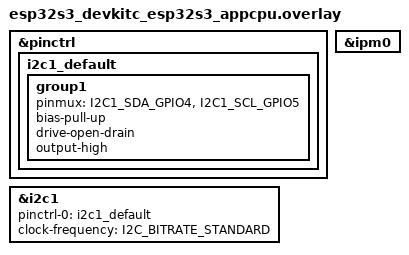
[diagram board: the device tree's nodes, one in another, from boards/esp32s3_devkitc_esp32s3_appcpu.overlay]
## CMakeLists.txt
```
cmake_minimum_required(VERSION 3.20.0)

find_package(Zephyr REQUIRED HINTS $ENV{ZEPHYR_BASE})
project(hw664_lis3dh_appcpu)

target_sources(app PRIVATE
	src/main.c
	src/ssd1306_display.c
)
```

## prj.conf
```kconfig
# 03_HW664_LIS3DH - core1 (appcpu) image
#
# This core never touches the accelerometer, only the SSD1306 over I2C1 and
# the IPM mailbox from core0.

CONFIG_I2C=y
CONFIG_GPIO=y

CONFIG_IPM=y
CONFIG_ESP32_SOFT_IPM=y

CONFIG_LOG=y
CONFIG_LOG_MODE_IMMEDIATE=y

CONFIG_FPU=y
```

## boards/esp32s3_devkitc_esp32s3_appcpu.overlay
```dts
/*
 * Overlay for 03_HW664_LIS3DH - core1 (appcpu) image
 *
 * Identical convention to Lab 01: I2C1 (NOT I2C0) at SDA=GPIO4 /
 * SCL=GPIO5, since core1 must own a physically different I2C
 * controller than core0's LIS3DSH bus. No sensor devicetree nodes
 * here - core1 never talks to the LIS3DSH directly, only to the
 * SSD1306 (probed at runtime by src/ssd1306_display.c).
 */

#include <dt-bindings/pinctrl/esp32s3-pinctrl.h>
#include <zephyr/dt-bindings/i2c/i2c.h>

&pinctrl {
	i2c1_default: i2c1_default {
		group1 {
			pinmux = <I2C1_SDA_GPIO4>, <I2C1_SCL_GPIO5>;
			bias-pull-up;
			drive-open-drain;
			output-high;
		};
	};
};

&i2c1 {
	status = "okay";
	pinctrl-0 = <&i2c1_default>;
	pinctrl-names = "default";
	clock-frequency = <I2C_BITRATE_STANDARD>; /* 100 kHz */
};

&ipm0 {
	status = "okay";
};
```

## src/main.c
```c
/*
 * main.c - 03_HW664_LIS3DH (core1 / appcpu image)
 *
 * CHIP IDENTITY CORRECTION (2026-09-04): the actual chip on this board
 * is an ST LIS3DH (WHO_AM_I=0x33 confirmed on real hardware), not a
 * genuine LIS3DSH (which would read 0x3F) despite the module's
 * silkscreen/listing. This core doesn't care either way - it only
 * ever sees the 3 accel values core0 forwards over IPM.
 *
 * Same pattern as Lab 01/02's core1: receive sensor snapshots from
 * core0 over IPM and draw them on the SSD1306. This core never touches
 * I2C0 or the accelerometer directly.
 *
 * Event flow: the ESP32 IPM driver invokes `ipm_callback()` in
 * interrupt context whenever core0 sends a message. ISR context must
 * stay short, so the callback only copies the payload into a message
 * queue (k_msgq_put with K_NO_WAIT is ISR-safe) and returns
 * immediately. The actual OLED redraw happens in `display_thread_fn()`,
 * which blocks on `k_msgq_get()` and only wakes when a new sample has
 * actually arrived.
 *
 * core0 pushes immediately when the accel vector magnitude moves past
 * a threshold since the last value it sent, plus a 1s heartbeat so
 * this side has something to declare "alive" during quiet periods.
 * This side only cares about elapsed time since the last arrival: if
 * nothing shows up in `sensor_msgq` for 2 s, the link is considered
 * down.
 */

#include <zephyr/kernel.h>
#include <zephyr/device.h>
#include <zephyr/drivers/i2c.h>
#include <zephyr/drivers/ipm.h>
#include <zephyr/logging/log.h>
#include <string.h>

#include "ipm_protocol.h"
#include "ssd1306_display.h"

LOG_MODULE_REGISTER(app_appcpu, LOG_LEVEL_INF);

static const struct device *dev_i2c1 = DEVICE_DT_GET(DT_NODELABEL(i2c1));
static const struct device *dev_ipm  = DEVICE_DT_GET(DT_NODELABEL(ipm0));

K_MSGQ_DEFINE(sensor_msgq, sizeof(struct ipm_sensor_payload), 4, 4);

/* Runs in IPM ISR context - keep it minimal. */
static void ipm_callback(const struct device *ipmdev, void *user_data,
			  uint32_t id, volatile void *data)
{
	ARG_UNUSED(ipmdev);
	ARG_UNUSED(user_data);

	if (id != IPM_SENSOR_CHANNEL) {
		return; /* not our channel - ignore */
	}

	struct ipm_sensor_payload payload;

	memcpy(&payload, (const void *)data, sizeof(payload));

	if (k_msgq_put(&sensor_msgq, &payload, K_NO_WAIT) != 0) {
		struct ipm_sensor_payload discard;

		k_msgq_get(&sensor_msgq, &discard, K_NO_WAIT);
		k_msgq_put(&sensor_msgq, &payload, K_NO_WAIT);
	}
}

static void format_fixed(float value, int decimals, char *buf, size_t buf_len)
{
	bool negative = value < 0.0f;
	float abs_value = negative ? -value : value;
	int scale = (decimals == 2) ? 100 : 10;
	int scaled = (int)(abs_value * scale + 0.5f);

	if (decimals == 2) {
		snprintf(buf, buf_len, "%s%d.%02d", negative ? "-" : "",
			  scaled / scale, scaled % scale);
	} else {
		snprintf(buf, buf_len, "%s%d.%d", negative ? "-" : "",
			  scaled / scale, scaled % scale);
	}
}

static void render_payload(const struct ipm_sensor_payload *p, bool stale)
{
	char line[22];
	char num[10];

	ssd1306_clear();

	/* Link health goes first/top - it qualifies how much to trust
	 * everything else on the screen.
	 */
	ssd1306_draw_text(0, 0, stale ? "LINK: FAIL" : "LINK: OK");

	if (p->valid) {
		format_fixed(p->accel_x_g, 2, num, sizeof(num));
		snprintf(line, sizeof(line), "AX:%s", num);
		ssd1306_draw_text(2, 0, line);

		format_fixed(p->accel_y_g, 2, num, sizeof(num));
		snprintf(line, sizeof(line), "AY:%s", num);
		ssd1306_draw_text(3, 0, line);

		format_fixed(p->accel_z_g, 2, num, sizeof(num));
		snprintf(line, sizeof(line), "AZ:%s", num);
		ssd1306_draw_text(4, 0, line);
	} else {
		ssd1306_draw_text(3, 0, "LIS3DH ---");
	}

	ssd1306_flush();
}

static void display_thread_fn(void *p1, void *p2, void *p3)
{
	ARG_UNUSED(p1);
	ARG_UNUSED(p2);
	ARG_UNUSED(p3);

	int ret = ssd1306_display_init(dev_i2c1);

	if (ret) {
		LOG_ERR("SSD1306 init failed: %d - display thread exiting", ret);
		return;
	}

	ssd1306_draw_text(3, 0, "WAITING FOR");
	ssd1306_draw_text(4, 0, "CORE0...");
	ssd1306_flush();

	bool have_data = false;
	struct ipm_sensor_payload last_payload = { 0 };

	while (1) {
		struct ipm_sensor_payload payload;
		int ret2 = k_msgq_get(&sensor_msgq, &payload, K_MSEC(2000));

		if (ret2 == 0) {
			last_payload = payload;
			have_data = true;
			render_payload(&last_payload, false);
		} else if (have_data) {
			render_payload(&last_payload, true);
		}
	}
}

K_THREAD_DEFINE(display_tid, 2048, display_thread_fn, NULL, NULL, NULL, 6, 0, 0);

int main(void)
{
	LOG_INF("03_HW664_LIS3DH (core1/appcpu) starting");

	if (!device_is_ready(dev_i2c1)) {
		LOG_ERR("I2C1 bus not ready");
		return -1;
	}
	if (!device_is_ready(dev_ipm)) {
		LOG_ERR("IPM device not ready - cannot receive sensor data from core0");
		return -1;
	}

	ipm_register_callback(dev_ipm, ipm_callback, NULL);
	ipm_set_enabled(dev_ipm, 1);

	/* display_thread_fn is already running (K_THREAD_DEFINE, 0 delay). */
	return 0;
}
```

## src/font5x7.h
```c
/*
 * font5x7.h
 *
 * Minimal original 5x7 dot-matrix font for the SSD1306 text
 * renderer used across this multi-sensor lab series. Only the
 * characters this series actually prints (labels, digits,
 * units, punctuation) are defined; anything else falls back
 * to a blank glyph in font5x7_lookup().
 *
 * Layout: 5 columns per glyph, column-major, bit0 = top row,
 * 7 rows tall (fits an 8px-tall character cell with 1px gap).
 */

#ifndef FONT5X7_H_
#define FONT5X7_H_

#include <stdint.h>
#include <stddef.h>
#include <zephyr/sys/util.h> /* ARRAY_SIZE */

#define FONT5X7_WIDTH  5
#define FONT5X7_HEIGHT 7

static const uint8_t FONT_SPACE[FONT5X7_WIDTH] = {0x00, 0x00, 0x00, 0x00, 0x00};
static const uint8_t FONT_BANG[FONT5X7_WIDTH] = {0x00, 0x5F, 0x5F, 0x00, 0x00};
static const uint8_t FONT_PERCENT[FONT5X7_WIDTH] = {0x21, 0x10, 0x0C, 0x02, 0x21};
static const uint8_t FONT_DASH[FONT5X7_WIDTH] = {0x08, 0x08, 0x08, 0x08, 0x08};
static const uint8_t FONT_DOT[FONT5X7_WIDTH] = {0x00, 0x60, 0x60, 0x00, 0x00};
static const uint8_t FONT_0[FONT5X7_WIDTH] = {0x3E, 0x51, 0x49, 0x45, 0x3E};
static const uint8_t FONT_1[FONT5X7_WIDTH] = {0x00, 0x42, 0x7F, 0x40, 0x00};
static const uint8_t FONT_2[FONT5X7_WIDTH] = {0x42, 0x61, 0x51, 0x49, 0x46};
static const uint8_t FONT_3[FONT5X7_WIDTH] = {0x22, 0x41, 0x49, 0x49, 0x36};
static const uint8_t FONT_4[FONT5X7_WIDTH] = {0x18, 0x14, 0x12, 0x7F, 0x10};
static const uint8_t FONT_5[FONT5X7_WIDTH] = {0x27, 0x45, 0x45, 0x45, 0x39};
static const uint8_t FONT_6[FONT5X7_WIDTH] = {0x3C, 0x4A, 0x49, 0x49, 0x30};
static const uint8_t FONT_7[FONT5X7_WIDTH] = {0x01, 0x71, 0x09, 0x05, 0x03};
static const uint8_t FONT_8[FONT5X7_WIDTH] = {0x36, 0x49, 0x49, 0x49, 0x36};
static const uint8_t FONT_9[FONT5X7_WIDTH] = {0x06, 0x49, 0x49, 0x29, 0x1E};
static const uint8_t FONT_COLON[FONT5X7_WIDTH] = {0x00, 0x36, 0x36, 0x00, 0x00};
static const uint8_t FONT_A[FONT5X7_WIDTH] = {0x7C, 0x12, 0x11, 0x12, 0x7C};
static const uint8_t FONT_B[FONT5X7_WIDTH] = {0x7F, 0x49, 0x49, 0x49, 0x36};
static const uint8_t FONT_C[FONT5X7_WIDTH] = {0x3E, 0x41, 0x41, 0x41, 0x41};
static const uint8_t FONT_D[FONT5X7_WIDTH] = {0x7F, 0x41, 0x41, 0x41, 0x3E};
static const uint8_t FONT_E[FONT5X7_WIDTH] = {0x7F, 0x49, 0x49, 0x49, 0x41};
static const uint8_t FONT_F[FONT5X7_WIDTH] = {0x7F, 0x09, 0x09, 0x09, 0x01};
static const uint8_t FONT_G[FONT5X7_WIDTH] = {0x3E, 0x41, 0x49, 0x49, 0x79};
static const uint8_t FONT_H[FONT5X7_WIDTH] = {0x7F, 0x08, 0x08, 0x08, 0x7F};
static const uint8_t FONT_I[FONT5X7_WIDTH] = {0x41, 0x41, 0x7F, 0x41, 0x41};
static const uint8_t FONT_L[FONT5X7_WIDTH] = {0x7F, 0x40, 0x40, 0x40, 0x40};
static const uint8_t FONT_M[FONT5X7_WIDTH] = {0x7F, 0x02, 0x04, 0x02, 0x7F};
static const uint8_t FONT_N[FONT5X7_WIDTH] = {0x7F, 0x02, 0x04, 0x08, 0x7F};
static const uint8_t FONT_O[FONT5X7_WIDTH] = {0x3E, 0x41, 0x41, 0x41, 0x3E};
static const uint8_t FONT_P[FONT5X7_WIDTH] = {0x7F, 0x09, 0x09, 0x09, 0x06};
static const uint8_t FONT_R[FONT5X7_WIDTH] = {0x7F, 0x09, 0x19, 0x29, 0x46};
static const uint8_t FONT_S[FONT5X7_WIDTH] = {0x46, 0x49, 0x49, 0x49, 0x31};
static const uint8_t FONT_T[FONT5X7_WIDTH] = {0x01, 0x01, 0x7F, 0x01, 0x01};
static const uint8_t FONT_U[FONT5X7_WIDTH] = {0x3F, 0x40, 0x40, 0x40, 0x3F};
static const uint8_t FONT_V[FONT5X7_WIDTH] = {0x1F, 0x20, 0x40, 0x20, 0x1F};
static const uint8_t FONT_W[FONT5X7_WIDTH] = {0x7F, 0x20, 0x18, 0x20, 0x7F};
static const uint8_t FONT_Y[FONT5X7_WIDTH] = {0x03, 0x04, 0x78, 0x04, 0x03};
static const uint8_t FONT_K[FONT5X7_WIDTH] = {0x7F, 0x08, 0x14, 0x22, 0x41};
static const uint8_t FONT_X[FONT5X7_WIDTH] = {0x41, 0x22, 0x1C, 0x22, 0x41};
static const uint8_t FONT_Z[FONT5X7_WIDTH] = {0x71, 0x49, 0x45, 0x43, 0x41};

struct font5x7_entry {
	char ch;
	const uint8_t *cols;
};

static const struct font5x7_entry font5x7_table[] = {
	{ ' ', FONT_SPACE },
	{ '!', FONT_BANG },
	{ '%', FONT_PERCENT },
	{ '-', FONT_DASH },
	{ '.', FONT_DOT },
	{ '0', FONT_0 },
	{ '1', FONT_1 },
	{ '2', FONT_2 },
	{ '3', FONT_3 },
	{ '4', FONT_4 },
	{ '5', FONT_5 },
	{ '6', FONT_6 },
	{ '7', FONT_7 },
	{ '8', FONT_8 },
	{ '9', FONT_9 },
	{ ':', FONT_COLON },
	{ 'A', FONT_A },
	{ 'B', FONT_B },
	{ 'C', FONT_C },
	{ 'D', FONT_D },
	{ 'E', FONT_E },
	{ 'F', FONT_F },
	{ 'G', FONT_G },
	{ 'H', FONT_H },
	{ 'I', FONT_I },
	{ 'L', FONT_L },
	{ 'M', FONT_M },
	{ 'N', FONT_N },
	{ 'O', FONT_O },
	{ 'P', FONT_P },
	{ 'R', FONT_R },
	{ 'S', FONT_S },
	{ 'T', FONT_T },
	{ 'U', FONT_U },
	{ 'V', FONT_V },
	{ 'W', FONT_W },
	{ 'Y', FONT_Y },
	{ 'K', FONT_K },
	{ 'X', FONT_X },
	{ 'Z', FONT_Z },
};

/* Returns the 5-byte column array for `ch`, or NULL if the
 * character isn't in the table (caller should render a blank).
 */
static inline const uint8_t *font5x7_lookup(char ch)
{
	for (size_t i = 0; i < ARRAY_SIZE(font5x7_table); i++) {
		if (font5x7_table[i].ch == ch) {
			return font5x7_table[i].cols;
		}
	}
	return NULL;
}

#endif /* FONT5X7_H_ */
```

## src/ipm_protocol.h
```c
/*
 * ipm_protocol.h
 *
 * Shared between the procpu (core0, src/) and appcpu (core1, remote/src/)
 * images. Sysbuild compiles these as two completely independent Zephyr
 * applications, so there is no shared build target to enforce a single
 * copy of this file - keep both copies byte-for-byte identical.
 */

#ifndef IPM_PROTOCOL_H_
#define IPM_PROTOCOL_H_

#include <stdint.h>

/* IPM channel used for procpu -> appcpu sensor forwarding. Same
 * channel number as Lab 01/02 - the labs are never flashed onto the
 * same board at once, so there's no real conflict.
 */
#define IPM_SENSOR_CHANNEL 2

/* 3-axis acceleration (g). No temperature channel this time - the
 * actual chip on this board is LIS3DH (see design doc), and Zephyr's
 * lis2dh driver doesn't expose a temperature channel for it.
 */
struct ipm_sensor_payload {
	float accel_x_g;
	float accel_y_g;
	float accel_z_g;
	uint8_t valid;
};

#endif /* IPM_PROTOCOL_H_ */
```

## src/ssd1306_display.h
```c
/*
 * ssd1306_display.h
 *
 * Minimal SSD1306 128x64 I2C text display driver, written raw against
 * the I2C API instead of Zephyr's in-tree display subsystem.
 *
 * Why raw I2C and not the official `solomon,ssd1306fb` driver + CFB:
 * this series' roadmap already root-caused a confirmed ESP32 Zephyr
 * I2C driver bug where multi-segment write transactions are not
 * reliably concatenated (see Lab 02 / parked SSD1306 I2C lab notes).
 * The official display driver issues the control byte and the pixel
 * payload as separate i2c messages, which reproduces that exact bug
 * on this SoC. This driver instead always merges the control byte and
 * the payload into ONE contiguous buffer and issues a single
 * `i2c_write()`, which is the workaround this series has already
 * validated on real hardware.
 */

#ifndef SSD1306_DISPLAY_H_
#define SSD1306_DISPLAY_H_

#include <zephyr/device.h>
#include <stdint.h>
#include <stdbool.h>

#define SSD1306_WIDTH  128
#define SSD1306_HEIGHT 64
#define SSD1306_PAGES  (SSD1306_HEIGHT / 8) /* 8 pages, 8 rows each */

/* Probes 0x3C then 0x3D (write-based probing, per this series' I2C0
 * convention), runs the panel init sequence, and clears the screen.
 * Returns 0 on success, -ENODEV if neither address responds, or a
 * negative I2C errno otherwise.
 */
int ssd1306_display_init(const struct device *i2c_dev);

/* Clears the in-RAM framebuffer only. Call ssd1306_flush() to push it
 * to the panel.
 */
void ssd1306_clear(void);

/* Draws a string using the 5x7 font at character-cell granularity.
 * `page` is 0..7 (each page is one 8px text row on a 64px-tall panel).
 * `col` is the starting pixel column, 0..127. Characters not present
 * in the font table render as a blank cell. Text is clipped, not
 * wrapped, if it would run past column 127.
 */
void ssd1306_draw_text(uint8_t page, uint8_t col, const char *text);

/* Pushes the in-RAM framebuffer to the panel as a single I2C write. */
int ssd1306_flush(void);

#endif /* SSD1306_DISPLAY_H_ */
```
